# STM32F100xx register map
File version: 1.1
Registers are 32-bit, read-write, reset 0x0 unless marked. A register's access mark holds for its fields unless they carry their own. Offsets are from the block's base; [hi:lo] are bit positions; {n}, {i} and the like mark numbered series.

## RTC — Real time clock
Base 0x40002800
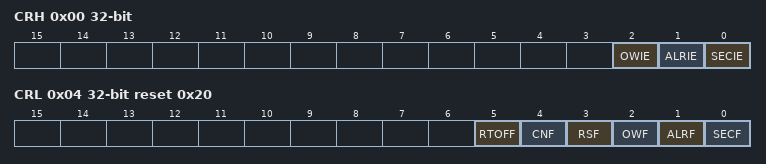
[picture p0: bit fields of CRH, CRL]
0x00 CRH — RTC Control Register High
  [2] OWIE — Overflow interrupt Enable
  [1] ALRIE — Alarm interrupt Enable
  [0] SECIE — Second interrupt Enable
0x04 CRL access per field reset 0x20 — RTC Control Register Low
  [5] RTOFF ro — RTC operation OFF
  [4] CNF rw — Configuration Flag
  [3] RSF rw — Registers Synchronized Flag
  [2] OWF rw — Overflow Flag
  [1] ALRF rw — Alarm Flag
  [0] SECF rw — Second Flag
0x08 PRLH wo — RTC Prescaler Load Register High
  [3:0] PRLH
0x0C PRLL wo reset 0x8000 — RTC Prescaler Load Register Low
  [15:0] PRLL — RTC Prescaler Divider Register Low
0x10 DIVH ro — RTC Prescaler Divider Register High
  [3:0] DIVH — RTC prescaler divider register high
0x14 DIVL ro reset 0x8000 — RTC Prescaler Divider Register Low
  [15:0] DIVL — RTC prescaler divider register Low
0x18 CNTH — RTC Counter Register High
  [15:0] CNTH — RTC counter register high
0x1C CNTL — RTC Counter Register Low
  [15:0] CNTL — RTC counter register Low
0x20 ALRH wo reset 0xFFFF — RTC Alarm Register High
  [15:0] ALRH — RTC alarm register high
0x24 ALRL wo reset 0xFFFF — RTC Alarm Register Low
  [15:0] ALRL — RTC alarm register low

## BKP — Backup registers
Base 0x40006C04
0x00 DR1 — Backup data register (BKP_DR)
  [15:0] D1 — Backup data
0x04 DR2 — Backup data register (BKP_DR)
  [15:0] D2 — Backup data
0x08 DR3 — Backup data register (BKP_DR)
  [15:0] D3 — Backup data
0x0C DR4 — Backup data register (BKP_DR)
  [15:0] D4 — Backup data
0x10 DR5 — Backup data register (BKP_DR)
  [15:0] D5 — Backup data
0x14 DR6 — Backup data register (BKP_DR)
  [15:0] D6 — Backup data
0x18 DR7 — Backup data register (BKP_DR)
  [15:0] D7 — Backup data
0x1C DR8 — Backup data register (BKP_DR)
  [15:0] D8 — Backup data
0x20 DR9 — Backup data register (BKP_DR)
  [15:0] D9 — Backup data
0x24 DR10 — Backup data register (BKP_DR)
  [15:0] D10 — Backup data
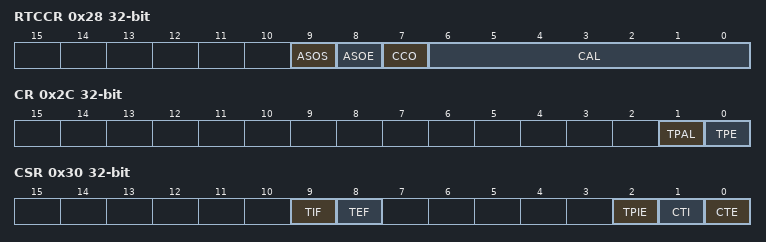
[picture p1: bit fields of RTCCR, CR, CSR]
0x28 RTCCR — RTC clock calibration register (BKP_RTCCR)
  [9] ASOS — Alarm or second output selection
  [8] ASOE — Alarm or second output enable
  [7] CCO — Calibration Clock Output
  [6:0] CAL — Calibration value
0x2C CR — Backup control register (BKP_CR)
  [1] TPAL — Tamper pin active level
  [0] TPE — Tamper pin enable
0x30 CSR access per field — BKP_CSR control/status register (BKP_CSR)
  [9] TIF ro — Tamper Interrupt Flag
  [8] TEF ro — Tamper Event Flag
  [2] TPIE rw — Tamper Pin interrupt enable
  [1] CTI wo — Clear Tamper Interrupt
  [0] CTE wo — Clear Tamper event
{0x10+4i} DR{i} (i=11..13) — Backup data register (BKP_DR)
  [15:0] DR{i} — Backup data
{0x10+4i} DR{i} (i=14..42) — Backup data register (BKP_DR)
  [15:0] D{i} — Backup data

## IWDG — Independent watchdog
Base 0x40003000
0x00 KR wo — Key register (IWDG_KR)
  [15:0] KEY — Key value
0x04 PR — Prescaler register (IWDG_PR)
  [2:0] PR — Prescaler divider
0x08 RLR reset 0xFFF — Reload register (IWDG_RLR)
  [11:0] RL — Watchdog counter reload value
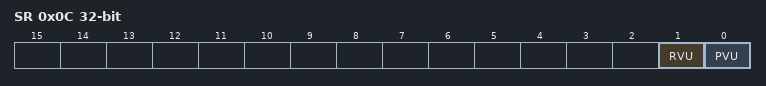
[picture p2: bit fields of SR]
0x0C SR ro — Status register (IWDG_SR)
  [1] RVU — Watchdog counter reload value update
  [0] PVU — Watchdog prescaler value update

## WWDG — Window watchdog
Base 0x40002C00
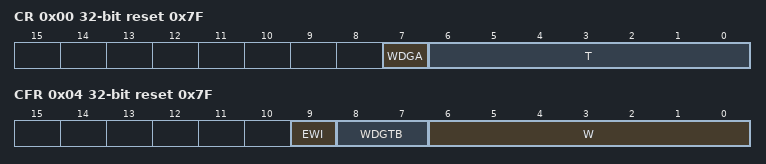
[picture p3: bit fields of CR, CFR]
0x00 CR reset 0x7F — Control register (WWDG_CR)
  [7] WDGA — Activation bit
  [6:0] T — 7-bit counter (MSB to LSB)
0x04 CFR reset 0x7F — Configuration register (WWDG_CFR)
  [9] EWI — Early Wakeup Interrupt
  [8:7] WDGTB — Timer Base
  [6:0] W — 7-bit window value
0x08 SR — Status register (WWDG_SR)
  [0] EWI — Early Wakeup Interrupt

## TIM12 — General purpose timer
Base 0x40001800
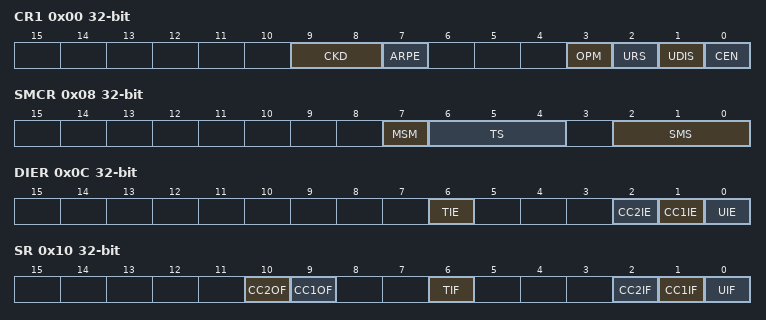
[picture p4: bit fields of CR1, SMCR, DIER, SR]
0x00 CR1 — control register 1
  [9:8] CKD — Clock division
  [7] ARPE — Auto-reload preload enable
  [3] OPM — One-pulse mode
  [2] URS — Update request source
  [1] UDIS — Update disable
  [0] CEN — Counter enable
0x04 CR2 — control register 2
  [6:4] MMS — Master mode selection
0x08 SMCR — slave mode control register
  [7] MSM — Master/Slave mode
  [6:4] TS — Trigger selection
  [2:0] SMS — Slave mode selection
0x0C DIER — DMA/Interrupt enable register
  [6] TIE — Trigger interrupt enable
  [2] CC2IE — Capture/Compare 2 interrupt enable
  [1] CC1IE — Capture/Compare 1 interrupt enable
  [0] UIE — Update interrupt enable
0x10 SR — status register
  [10] CC2OF — Capture/compare 2 overcapture flag
  [9] CC1OF — Capture/Compare 1 overcapture flag
  [6] TIF — Trigger interrupt flag
  [2] CC2IF — Capture/Compare 2 interrupt flag
  [1] CC1IF — Capture/compare 1 interrupt flag
  [0] UIF — Update interrupt flag
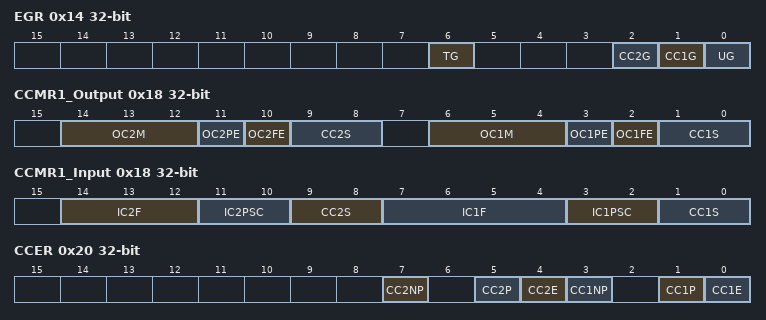
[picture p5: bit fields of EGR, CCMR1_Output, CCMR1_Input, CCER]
0x14 EGR wo — event generation register
  [6] TG — Trigger generation
  [2] CC2G — Capture/compare 2 generation
  [1] CC1G — Capture/compare 1 generation
  [0] UG — Update generation
0x18 CCMR1_Output — capture/compare mode register 1 (output mode)
  [14:12] OC2M — Output Compare 2 mode
  [11] OC2PE — Output Compare 2 preload enable
  [10] OC2FE — Output Compare 2 fast enable
  [9:8] CC2S — Capture/Compare 2 selection
  [6:4] OC1M — Output Compare 1 mode
  [3] OC1PE — Output Compare 1 preload enable
  [2] OC1FE — Output Compare 1 fast enable
  [1:0] CC1S — Capture/Compare 1 selection
0x18 CCMR1_Input (alternate view of CCMR1_Output) — capture/compare mode register 1 (input mode)
  [14:12] IC2F — Input capture 2 filter
  [11:10] IC2PSC — Input capture 2 prescaler
  [9:8] CC2S — Capture/Compare 2 selection
  [7:4] IC1F — Input capture 1 filter
  [3:2] IC1PSC — Input capture 1 prescaler
  [1:0] CC1S — Capture/Compare 1 selection
0x20 CCER — capture/compare enable register
  [7] CC2NP — Capture/Compare 2 output Polarity
  [5] CC2P — Capture/Compare 2 output Polarity
  [4] CC2E — Capture/Compare 2 output enable
  [3] CC1NP — Capture/Compare 1 output Polarity
  [1] CC1P — Capture/Compare 1 output Polarity
  [0] CC1E — Capture/Compare 1 output enable
0x24 CNT — counter
  [15:0] CNT — counter value
0x28 PSC — prescaler
  [15:0] PSC — Prescaler value
0x2C ARR — auto-reload register
  [15:0] ARR — Auto-reload value
0x34 CCR1 — capture/compare register 1
  [15:0] CCR1 — Capture/Compare 1 value
0x38 CCR2 — capture/compare register 2
  [15:0] CCR2 — Capture/Compare 2 value
